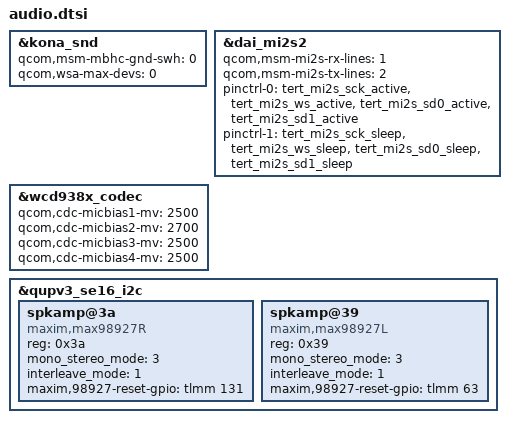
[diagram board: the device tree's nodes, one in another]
 /*
 * nubia overwrite dts
 */

&kona_snd {
	qcom,msm-mbhc-gnd-swh = <0>;
	qcom,wsa-max-devs = <0>;
};

&dai_mi2s2 {
	qcom,msm-mi2s-rx-lines = <1>;
	qcom,msm-mi2s-tx-lines = <2>;
	pinctrl-names = "default", "sleep";
	pinctrl-0 = <&tert_mi2s_sck_active &tert_mi2s_ws_active
			&tert_mi2s_sd0_active &tert_mi2s_sd1_active>;
	pinctrl-1 = <&tert_mi2s_sck_sleep &tert_mi2s_ws_sleep
			&tert_mi2s_sd0_sleep &tert_mi2s_sd1_sleep>;
};

&wcd938x_codec{
	qcom,cdc-micbias1-mv = <2500>;
	qcom,cdc-micbias2-mv = <2700>;
	qcom,cdc-micbias3-mv = <2500>;
	qcom,cdc-micbias4-mv = <2500>;
};

&qupv3_se16_i2c {
	status = "ok";

	spkamp@3a {/* max98927 smartpa device*/
		compatible = "maxim,max98927R";
		status = "okay";
		reg = <0x3a>;
		mono_stereo_mode = <3>;
		interleave_mode = <1>;
		maxim,98927-reset-gpio = <&tlmm 131 0>;
	};

	spkamp@39 {/* max98927 smartpa device*/
		compatible = "maxim,max98927L";
		status = "okay";
		reg = <0x39>;
		mono_stereo_mode = <3>;
		interleave_mode = <1>;
		maxim,98927-reset-gpio = <&tlmm 63 0>;
	};
};
